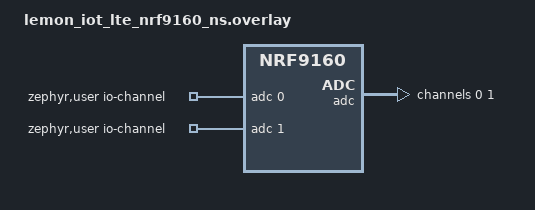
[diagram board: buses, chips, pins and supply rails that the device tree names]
/*
 * Copyright (c) 2023 Aaron Mohtar & Co Pty Ltd
 *
 * SPDX-License-Identifier: Apache-2.0
 */

/ {
	zephyr,user {
		io-channels = <&adc 0>, <&adc 1>;
	};
};

&adc {
	status = "okay";
	#address-cells = <1>;
	#size-cells = <0>;

	channel@0 {
		reg = <0>;
		zephyr,gain = "ADC_GAIN_1_6";
		zephyr,reference = "ADC_REF_INTERNAL";		// 600mV Bandgap
		zephyr,vref-mv = <600>;
		zephyr,acquisition-time = <ADC_ACQ_TIME_DEFAULT>;
		zephyr,input-positive = <NRF_SAADC_AIN0>;	// P0.13
		zephyr,resolution = <12>;
	};

	channel@1 {
		reg = <1>;
		zephyr,gain = "ADC_GAIN_1_6";
		zephyr,reference = "ADC_REF_INTERNAL";
		zephyr,vref-mv = <600>;
		zephyr,acquisition-time = <ADC_ACQ_TIME_DEFAULT>;
		zephyr,input-positive = <NRF_SAADC_VDD>;
		zephyr,resolution = <14>;
		zephyr,oversampling = <8>;
	};
};
